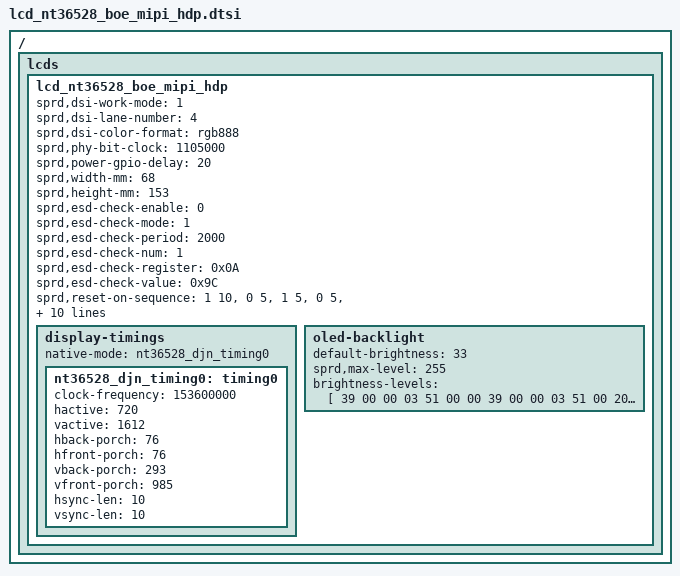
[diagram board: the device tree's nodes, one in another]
// SPDX-License-Identifier: GPL-2.0-only
/*
 * Unisoc ili9881c Truly LCD config DTS file
 *
 * Copyright (C) 2021, Unisoc Inc.
 */
/ {
	fragment {
		target-path = "/";
		__overlay__ {
			lcds {
				lcd_nt36528_boe_mipi_hdp: lcd_nt36528_boe_mipi_hdp {
					sprd,dsi-work-mode = <1>; /* video burst mode*/
					sprd,dsi-lane-number = <4>;
					sprd,dsi-color-format = "rgb888";

					sprd,phy-bit-clock = <1105000>; /* kbps */
					//sprd,phy-escape-clock = <20000>;/* kHz */
					//sprd,dpi-clk-div = <1>;
					sprd,power-gpio-delay = <20>;/* ms */

					//sprd,lcm_ic_name = "NT36528";
					//sprd,lcm_ic_vendor = "DJN";
					//sprd,lcm_ic_inch = "6.56";

					sprd,width-mm = <68>;
					sprd,height-mm = <153>;

					sprd,esd-check-enable = <0>;
					sprd,esd-check-mode = <1>;
					sprd,esd-check-period = <2000>;
					sprd,esd-check-num = <1>;
					sprd,esd-check-register = <0x0A>;
					sprd,esd-check-value = <0x9C>;

					sprd,reset-on-sequence = <1 10>, <0 5>, <1 5>, <0 5>, <1 20>;
					sprd,reset-off-sequence = <1 5>;

					sprd,initial-command = [
						23 00 00 02 FF 20
						23 00 00 02 FB 01
						23 00 00 02 07 B4
						23 00 00 02 08 B4
						23 00 00 02 0D 80
						23 00 00 02 1F 22
						23 00 00 02 82 66
						23 00 00 02 89 BE
						23 00 00 02 8B BE
						23 00 00 02 94 C0
						23 00 00 02 95 13
						23 00 00 02 96 13
						23 00 00 02 FF 24
						23 00 00 02 FB 01
						23 00 00 02 01 26
						23 00 00 02 02 21
						23 00 00 02 03 04
						23 00 00 02 04 05
						23 00 00 02 05 0C
						23 00 00 02 06 0D
						23 00 00 02 07 0E
						23 00 00 02 08 0F
						23 00 00 02 09 10
						23 00 00 02 0A 11
						23 00 00 02 0B 12
						23 00 00 02 0C 13
						23 00 00 02 0D 20
						23 00 00 02 17 26
						23 00 00 02 18 21
						23 00 00 02 19 04
						23 00 00 02 1A 05
						23 00 00 02 1B 0C
						23 00 00 02 1C 0D
						23 00 00 02 1D 0E
						23 00 00 02 1E 0F
						23 00 00 02 1F 10
						23 00 00 02 20 11
						23 00 00 02 21 12
						23 00 00 02 22 13
						23 00 00 02 23 20
						23 00 00 02 2F 11
						23 00 00 02 30 0D
						23 00 00 02 33 0D
						23 00 00 02 34 11
						23 00 00 02 37 88
						23 00 00 02 3A 06
						23 00 00 02 3B C8
						23 00 00 02 3D 52
						23 00 00 02 50 87
						23 00 00 02 51 78
						23 00 00 02 52 56
						23 00 00 02 53 34
						23 00 00 02 54 12
						39 00 00 03 55 4E 0E
						23 00 00 02 56 08
						23 00 00 02 5C 8A
						23 00 00 02 5D 0A
						39 00 00 03 5E 00 08
						23 00 00 02 AF 12
						23 00 00 02 B0 09
						23 00 00 02 B1 12
						23 00 00 02 B2 09
						23 00 00 02 FF 25
						23 00 00 02 FB 01
						23 00 00 02 44 06
						23 00 00 02 5D 06
						23 00 00 02 5E C8
						23 00 00 02 C0 8C
						23 00 00 02 C6 11
						23 00 00 02 FF 26
						23 00 00 02 FB 01
						23 00 00 02 4D 06
						23 00 00 02 4E 78
						23 00 00 02 6E 06
						23 00 00 02 6F 78
						23 00 00 02 7B 06
						23 00 00 02 7C 78
						23 00 00 02 FF 27
						23 00 00 02 FB 01
						23 00 00 02 14 66
						23 00 00 02 15 D8
						23 00 00 02 1A 66
						23 00 00 02 1B 66
						23 00 00 02 78 98
						23 00 00 02 79 0F
						23 00 00 02 7A 0F
						23 00 00 02 7C 0A
						23 00 00 02 7D 69
						23 00 00 02 7E 0A
						23 00 00 02 7F 69
						23 00 00 02 80 0A
						23 00 00 02 81 69
						23 00 00 02 83 12
						23 00 00 02 84 0E
						23 00 00 02 87 0E
						23 00 00 02 88 12
						23 00 00 02 93 80
						23 00 00 02 94 80
						23 00 00 02 96 0B
						23 00 00 02 97 15
						23 00 00 02 98 88
						23 00 00 02 C4 06
						23 00 00 02 C5 78
						23 00 00 02 C6 06
						23 00 00 02 C7 78
						23 00 00 02 E4 00
						23 00 00 02 E5 9D
						23 00 00 02 FF 2A
						23 00 00 02 FB 01
						23 00 00 02 64 96
						23 00 00 02 67 16
						23 00 00 02 6A 96
						23 00 00 02 73 9E
						23 00 00 02 76 9E
						23 00 00 02 79 16
						23 00 00 02 7C 16
						23 00 00 02 7F 96
						23 00 00 02 82 16
						23 00 00 02 85 16
						23 00 00 02 A2 3F
						23 00 00 02 A3 FF
						23 00 00 02 A4 C3
						23 00 00 02 FF 24
						23 00 00 02 FB 01
						23 00 00 02 59 70
						23 00 00 02 5A BC
						23 00 00 02 5B AA
						23 00 00 02 61 4C
						23 00 00 02 92 CE
						39 00 00 03 93 12 00
						23 00 00 02 94 C8
						23 00 00 02 DC C9
						23 00 00 02 E0 C9
						23 00 00 02 E2 C9
						23 00 00 02 E4 C9
						23 00 00 02 E6 C9
						23 00 00 02 EA C9
						23 00 00 02 EE C9
						23 00 00 02 F0 C9
						23 00 00 02 FF 25
						23 00 00 02 FB 01
						23 00 00 02 13 02
						23 00 00 02 14 72
						23 00 00 02 15 01
						23 00 00 02 16 8B
						23 00 00 02 1F BC
						23 00 00 02 20 AA
						23 00 00 02 26 BC
						23 00 00 02 27 AA
						23 00 00 02 48 BC
						23 00 00 02 49 AA
						23 00 00 02 50 BC
						23 00 00 02 51 AA
						23 00 00 02 61 BC
						23 00 00 02 62 AA
						23 00 00 02 68 08
						23 00 00 02 BC 24
						23 00 00 02 FF 26
						23 00 00 02 FB 01
						23 00 00 02 00 80
						23 00 00 02 02 0D
						23 00 00 02 04 2F
						23 00 00 02 09 05
						23 00 00 02 0A 05
						23 00 00 02 19 0B
						23 00 00 02 1A 54
						23 00 00 02 1B 0A
						23 00 00 02 1C C9
						23 00 00 02 1E CE
						23 00 00 02 1F CE
						23 00 00 02 24 00
						23 00 00 02 25 CE
						23 00 00 02 2A 0B
						23 00 00 02 2B 54
						23 00 00 02 2F 05
						23 00 00 02 30 CE
						23 00 00 02 32 CE
						23 00 00 02 37 11
						23 00 00 02 38 01
						23 00 00 02 39 08
						23 00 00 02 3A CE
						23 00 00 02 40 81
						23 00 00 02 41 81
						23 00 00 02 42 81
						23 00 00 02 44 81
						23 00 00 02 46 81
						23 00 00 02 48 81
						23 00 00 02 49 08
						23 00 00 02 4A 81
						23 00 00 02 51 7B
						23 00 00 02 52 69
						23 00 00 02 56 7B
						23 00 00 02 58 69
						23 00 00 02 5B 7B
						23 00 00 02 5C 69
						23 00 00 02 60 7B
						23 00 00 02 61 69
						23 00 00 02 64 7B
						23 00 00 02 65 69
						23 00 00 02 69 7B
						23 00 00 02 6A 69
						23 00 00 02 72 7B
						23 00 00 02 73 69
						23 00 00 02 8B 35
						23 00 00 02 8C 09
						23 00 00 02 8D 00
						23 00 00 02 99 0B
						23 00 00 02 9A 54
						23 00 00 02 9B 0A
						23 00 00 02 9C C9
						23 00 00 02 9D 0B
						23 00 00 02 9E 54
						23 00 00 02 C3 00
						23 00 00 02 FF 27
						23 00 00 02 FB 01
						23 00 00 02 58 A4
						39 00 00 03 59 00 12
						39 00 00 03 5A 00 C3
						39 00 00 03 5D 00 01
						39 00 00 03 5E 00 B1
						23 00 00 02 5F 01
						39 00 00 03 60 06 75
						23 00 00 02 C0 08
						23 00 00 02 F0 77
						23 00 00 02 F1 10
						23 00 00 02 F4 00
						23 00 00 02 F5 77
						23 00 00 02 FF 2A
						23 00 00 02 FB 01
						23 00 00 02 04 7C
						23 00 00 02 06 7C
						23 00 00 02 09 7C
						23 00 00 02 0B 7C
						23 00 00 02 0D 7C
						23 00 00 02 14 7C
						23 00 00 02 15 7C
						23 00 00 02 16 7C
						23 00 00 02 23 0C
						23 00 00 02 28 12
						23 00 00 02 2D 12
						23 00 00 02 33 12
						23 00 00 02 35 0A
						23 00 00 02 37 79
						23 00 00 02 99 95
						23 00 00 02 9A 0B
						23 00 00 02 C4 80
						23 00 00 02 C5 12
						23 00 00 02 C6 01
						23 00 00 02 C7 2A
						23 00 00 02 C8 10
						23 00 00 02 C9 01
						23 00 00 02 CA 18
						23 00 00 02 CB 16
						23 00 00 02 CC 75
						23 00 00 02 FF 23
						23 00 00 02 FB 01
						23 00 00 02 00 80
						23 00 00 02 07 00
						23 00 00 02 08 01
						23 00 00 02 09 1F
						23 00 00 02 11 00
						23 00 00 02 12 B5
						23 00 00 02 15 E7
						23 00 00 02 16 14
						23 00 00 02 FF 25
						23 00 00 02 FB 01
						39 00 00 05 02 00 40 00 40
						23 00 00 02 FF 27
						23 00 00 02 FB 01
						23 00 00 02 E9 02
						23 00 00 02 FF 2A
						23 00 00 02 FB 01
						23 00 00 02 99 95
						23 00 00 02 9A 0B
						23 00 00 02 AC 00
						23 00 00 02 AD 3C
						23 00 00 02 AE 80
						23 00 00 02 AF 43
						23 00 00 02 B0 18
						23 00 00 02 B1 90
						23 00 00 02 B3 22
						23 00 00 02 FF 10
						23 00 00 02 FB 01
						23 00 00 02 BA 03
						23 00 00 02 FF 25
						23 00 00 02 FB 01
						23 00 00 02 BC 24
						23 00 00 02 FF 26
						23 00 00 02 FB 01
						23 00 00 02 09 05
						23 00 00 02 FF 2A
						23 00 00 02 FB 01
						23 00 00 02 23 0C
						23 00 00 02 FF 10
						23 00 00 02 FB 01
						23 00 00 02 55 00
						23 00 00 02 53 2C
						39 00 00 03 51 00 00
						23 00 00 02 35 00
						13 78 00 01 11
						13 14 00 01 29
						];

					sprd,sleep-in-command = [
						13 14 00 01 28
						13 78 00 01 10
						];

					sprd,sleep-out-command = [
						13 78 00 01 11
						13 14 00 01 29
						];

					sprd,oled-backlight-close = [
						39 00 00 03 51 00 00
						];

					display-timings {
						native-mode = <&nt36528_djn_timing0>;

						nt36528_djn_timing0: timing0 {
							clock-frequency = <153600000>;
							hactive = <720>;
							vactive = <1612>;
							hback-porch = <76>;
							hfront-porch = <76>;
							vback-porch = <293>;
							vfront-porch = <985>;
							hsync-len = <10>;
							vsync-len = <10>;
						};
						//nt36528_djn_timing1: timing1 {
						//	clock-frequency = <153600000>;
						//	hactive = <720>;
						//	vactive = <1612>;
						//	hback-porch = <76>;
						//	hfront-porch = <76>;
						//	vback-porch = <293>;
						//	vfront-porch = <18>;
						//	hsync-len = <10>;
						//	vsync-len = <10>;
						//};
					};

					oled-backlight {
						default-brightness = <33>;
						sprd,max-level = <255>;
						brightness-levels = [
							39 00 00 03 51 00 00
							39 00 00 03 51 00 20
							39 00 00 03 51 00 30
							39 00 00 03 51 00 40
							39 00 00 03 51 00 50
							39 00 00 03 51 00 60
							39 00 00 03 51 00 70
							39 00 00 03 51 00 80
							39 00 00 03 51 00 90
							39 00 00 03 51 00 A0
							39 00 00 03 51 00 B0
							39 00 00 03 51 00 C0
							39 00 00 03 51 00 D0
							39 00 00 03 51 00 E0
							39 00 00 03 51 00 F0
							39 00 00 03 51 01 00
							39 00 00 03 51 01 11
							39 00 00 03 51 01 21
							39 00 00 03 51 01 31
							39 00 00 03 51 01 41
							39 00 00 03 51 01 51
							39 00 00 03 51 01 61
							39 00 00 03 51 01 71
							39 00 00 03 51 01 81
							39 00 00 03 51 01 91
							39 00 00 03 51 01 A1
							39 00 00 03 51 01 B1
							39 00 00 03 51 01 C1
							39 00 00 03 51 01 D1
							39 00 00 03 51 01 E1
							39 00 00 03 51 01 F1
							39 00 00 03 51 02 01
							39 00 00 03 51 02 11
							39 00 00 03 51 02 22
							39 00 00 03 51 02 32
							39 00 00 03 51 02 42
							39 00 00 03 51 02 52
							39 00 00 03 51 02 62
							39 00 00 03 51 02 72
							39 00 00 03 51 02 82
							39 00 00 03 51 02 92
							39 00 00 03 51 02 A2
							39 00 00 03 51 02 B2
							39 00 00 03 51 02 C2
							39 00 00 03 51 02 D2
							39 00 00 03 51 02 E2
							39 00 00 03 51 02 F2
							39 00 00 03 51 03 02
							39 00 00 03 51 03 12
							39 00 00 03 51 03 22
							39 00 00 03 51 03 32
							39 00 00 03 51 03 43
							39 00 00 03 51 03 53
							39 00 00 03 51 03 63
							39 00 00 03 51 03 73
							39 00 00 03 51 03 83
							39 00 00 03 51 03 93
							39 00 00 03 51 03 A3
							39 00 00 03 51 03 B3
							39 00 00 03 51 03 C3
							39 00 00 03 51 03 D3
							39 00 00 03 51 03 E3
							39 00 00 03 51 03 F3
							39 00 00 03 51 04 03
							39 00 00 03 51 04 13
							39 00 00 03 51 04 23
							39 00 00 03 51 04 33
							39 00 00 03 51 04 43
							39 00 00 03 51 04 54
							39 00 00 03 51 04 64
							39 00 00 03 51 04 74
							39 00 00 03 51 04 84
							39 00 00 03 51 04 94
							39 00 00 03 51 04 A4
							39 00 00 03 51 04 B4
							39 00 00 03 51 04 C4
							39 00 00 03 51 04 D4
							39 00 00 03 51 04 E4
							39 00 00 03 51 04 F4
							39 00 00 03 51 05 04
							39 00 00 03 51 05 14
							39 00 00 03 51 05 24
							39 00 00 03 51 05 34
							39 00 00 03 51 05 44
							39 00 00 03 51 05 54
							39 00 00 03 51 05 65
							39 00 00 03 51 05 75
							39 00 00 03 51 05 85
							39 00 00 03 51 05 95
							39 00 00 03 51 05 A5
							39 00 00 03 51 05 B5
							39 00 00 03 51 05 C5
							39 00 00 03 51 05 D5
							39 00 00 03 51 05 E5
							39 00 00 03 51 05 F5
							39 00 00 03 51 06 05
							39 00 00 03 51 06 15
							39 00 00 03 51 06 25
							39 00 00 03 51 06 35
							39 00 00 03 51 06 45
							39 00 00 03 51 06 55
							39 00 00 03 51 06 65
							39 00 00 03 51 06 76
							39 00 00 03 51 06 86
							39 00 00 03 51 06 96
							39 00 00 03 51 06 A6
							39 00 00 03 51 06 B6
							39 00 00 03 51 06 C6
							39 00 00 03 51 06 D6
							39 00 00 03 51 06 E6
							39 00 00 03 51 06 F6
							39 00 00 03 51 07 06
							39 00 00 03 51 07 16
							39 00 00 03 51 07 26
							39 00 00 03 51 07 36
							39 00 00 03 51 07 46
							39 00 00 03 51 07 56
							39 00 00 03 51 07 66
							39 00 00 03 51 07 76
							39 00 00 03 51 07 87
							39 00 00 03 51 07 97
							39 00 00 03 51 07 A7
							39 00 00 03 51 07 B7
							39 00 00 03 51 07 C7
							39 00 00 03 51 07 D7
							39 00 00 03 51 07 E7
							39 00 00 03 51 07 F7
							39 00 00 03 51 08 07
							39 00 00 03 51 08 17
							39 00 00 03 51 08 27
							39 00 00 03 51 08 37
							39 00 00 03 51 08 47
							39 00 00 03 51 08 57
							39 00 00 03 51 08 67
							39 00 00 03 51 08 77
							39 00 00 03 51 08 87
							39 00 00 03 51 08 98
							39 00 00 03 51 08 A8
							39 00 00 03 51 08 B8
							39 00 00 03 51 08 C8
							39 00 00 03 51 08 D8
							39 00 00 03 51 08 E8
							39 00 00 03 51 08 F8
							39 00 00 03 51 09 08
							39 00 00 03 51 09 18
							39 00 00 03 51 09 28
							39 00 00 03 51 09 38
							39 00 00 03 51 09 48
							39 00 00 03 51 09 58
							39 00 00 03 51 09 68
							39 00 00 03 51 09 78
							39 00 00 03 51 09 88
							39 00 00 03 51 09 98
							39 00 00 03 51 09 A9
							39 00 00 03 51 09 B9
							39 00 00 03 51 09 C9
							39 00 00 03 51 09 D9
							39 00 00 03 51 09 E9
							39 00 00 03 51 09 F9
							39 00 00 03 51 0A 09
							39 00 00 03 51 0A 19
							39 00 00 03 51 0A 29
							39 00 00 03 51 0A 39
							39 00 00 03 51 0A 49
							39 00 00 03 51 0A 59
							39 00 00 03 51 0A 69
							39 00 00 03 51 0A 79
							39 00 00 03 51 0A 89
							39 00 00 03 51 0A 99
							39 00 00 03 51 0A A9
							39 00 00 03 51 0A BA
							39 00 00 03 51 0A CA
							39 00 00 03 51 0A DA
							39 00 00 03 51 0A EA
							39 00 00 03 51 0A FA
							39 00 00 03 51 0B 0A
							39 00 00 03 51 0B 1A
							39 00 00 03 51 0B 2A
							39 00 00 03 51 0B 3A
							39 00 00 03 51 0B 4A
							39 00 00 03 51 0B 5A
							39 00 00 03 51 0B 6A
							39 00 00 03 51 0B 7A
							39 00 00 03 51 0B 8A
							39 00 00 03 51 0B 9A
							39 00 00 03 51 0B AA
							39 00 00 03 51 0B BA
							39 00 00 03 51 0B CB
							39 00 00 03 51 0B DB
							39 00 00 03 51 0B EB
							39 00 00 03 51 0B FB
							39 00 00 03 51 0C 0B
							39 00 00 03 51 0C 1B
							39 00 00 03 51 0C 2B
							39 00 00 03 51 0C 3B
							39 00 00 03 51 0C 4B
							39 00 00 03 51 0C 5B
							39 00 00 03 51 0C 6B
							39 00 00 03 51 0C 7B
							39 00 00 03 51 0C 8B
							39 00 00 03 51 0C 9B
							39 00 00 03 51 0C AB
							39 00 00 03 51 0C BB
							39 00 00 03 51 0C CB
							39 00 00 03 51 0C DC
							39 00 00 03 51 0C EC
							39 00 00 03 51 0C FC
							39 00 00 03 51 0D 0C
							39 00 00 03 51 0D 1C
							39 00 00 03 51 0D 2C
							39 00 00 03 51 0D 3C
							39 00 00 03 51 0D 4C
							39 00 00 03 51 0D 5C
							39 00 00 03 51 0D 6C
							39 00 00 03 51 0D 7C
							39 00 00 03 51 0D 8C
							39 00 00 03 51 0D 9C
							39 00 00 03 51 0D AC
							39 00 00 03 51 0D BC
							39 00 00 03 51 0D CC
							39 00 00 03 51 0D DC
							39 00 00 03 51 0D ED
							39 00 00 03 51 0D FD
							39 00 00 03 51 0E 0D
							39 00 00 03 51 0E 1D
							39 00 00 03 51 0E 2D
							39 00 00 03 51 0E 3D
							39 00 00 03 51 0E 4D
							39 00 00 03 51 0E 5D
							39 00 00 03 51 0E 6D
							39 00 00 03 51 0E 7D
							39 00 00 03 51 0E 8D
							39 00 00 03 51 0E 9D
							39 00 00 03 51 0E AD
							39 00 00 03 51 0E BD
							39 00 00 03 51 0E CD
							39 00 00 03 51 0E DD
							39 00 00 03 51 0E ED
							39 00 00 03 51 0E FE
							39 00 00 03 51 0F 0E
							39 00 00 03 51 0F 1E
							39 00 00 03 51 0F 2E
							39 00 00 03 51 0F 3E
							39 00 00 03 51 0F 4E
							39 00 00 03 51 0F 5E
							39 00 00 03 51 0F 6E
							39 00 00 03 51 0F 7E
							39 00 00 03 51 0F 8E
							39 00 00 03 51 0F 9E
							39 00 00 03 51 0F AE
							39 00 00 03 51 0F BE
							39 00 00 03 51 0F CE
							39 00 00 03 51 0F DE
							39 00 00 03 51 0F EE
							39 00 00 03 51 0F FE
							39 00 00 03 51 0F FE
						];
					};
				};
			};
		};
	};
};
